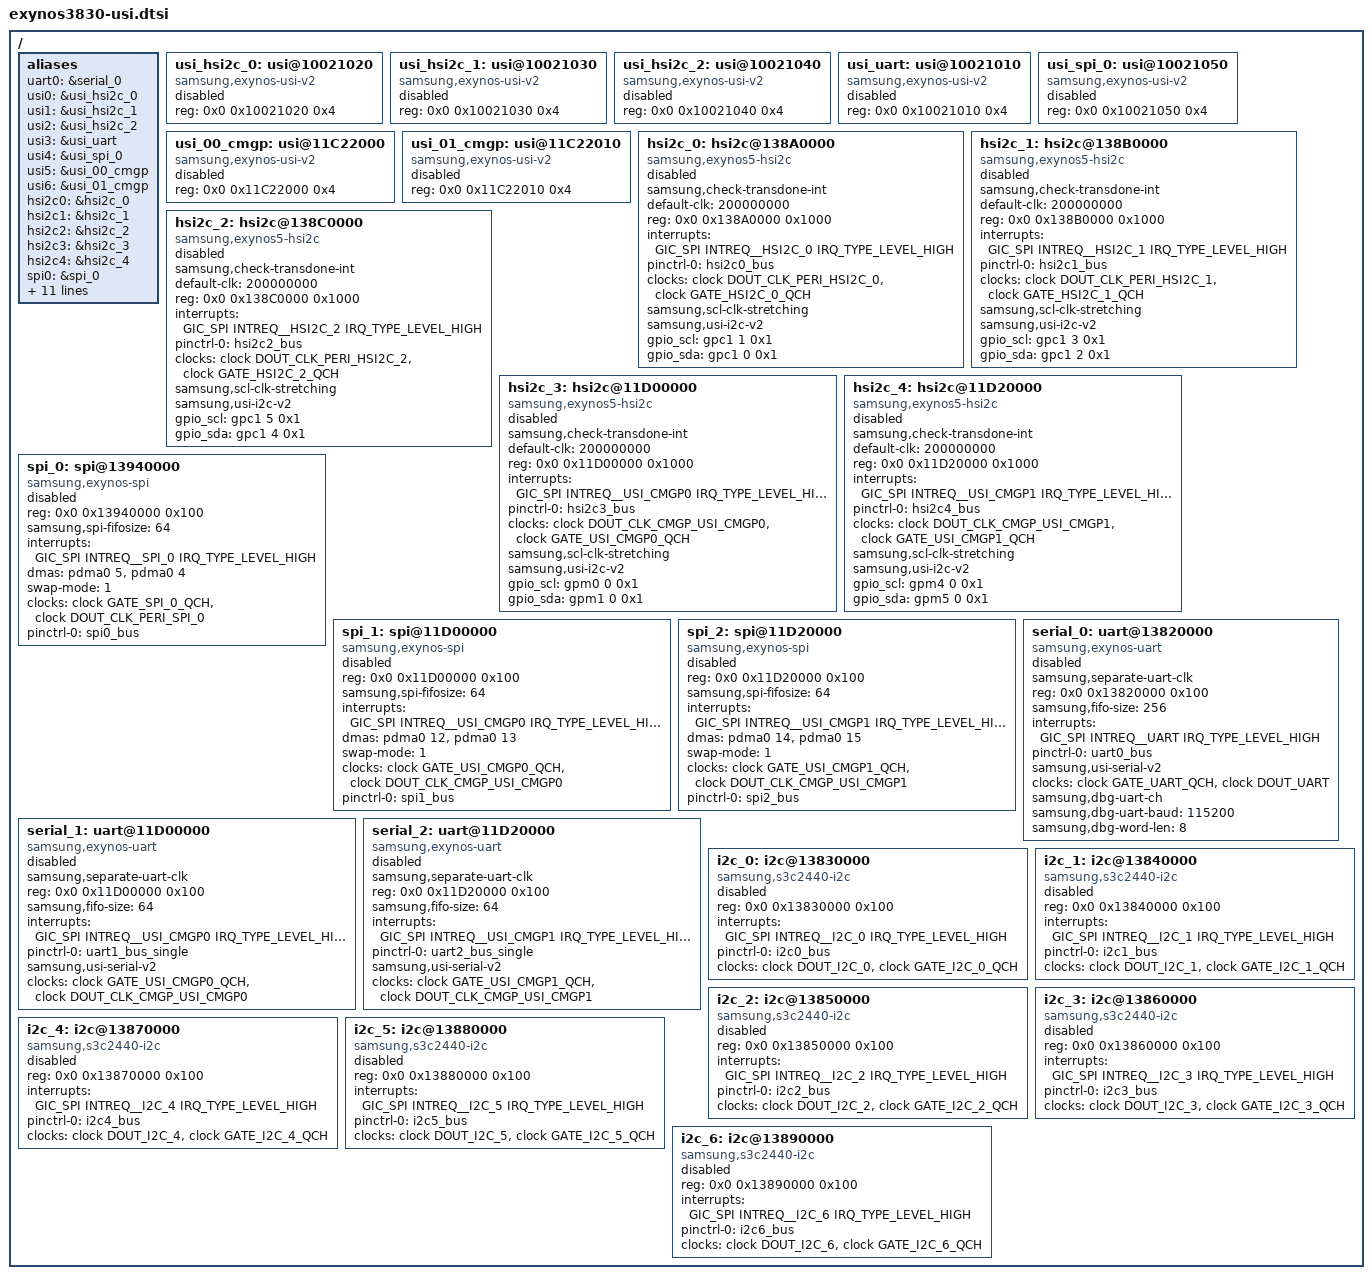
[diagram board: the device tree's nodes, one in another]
/*
 * Samsung's Exynos3830 SoC USI device tree source
 *
 * Copyright (c) 2019 Samsung Electronics Co., Ltd.
 *		http://www.samsung.com
 *
 * Samsung's Exynos3830 SoC USI channels are listed as device
 * tree nodes are listed in this file.
 *
 * This program is free software; you can redistribute it and/or modify
 * it under the terms of the GNU General Public License version 2 as
 * published by the Free Software Foundation.
*/

/ {
	aliases {
		uart0 = &serial_0;
		usi0 = &usi_hsi2c_0;
		usi1 = &usi_hsi2c_1;
		usi2 = &usi_hsi2c_2;
		usi3 = &usi_uart;
		usi4 = &usi_spi_0;
		usi5 = &usi_00_cmgp;
		usi6 = &usi_01_cmgp;
		hsi2c0 = &hsi2c_0;
		hsi2c1 = &hsi2c_1;
		hsi2c2 = &hsi2c_2;
		hsi2c3 = &hsi2c_3;
		hsi2c4 = &hsi2c_4;
		spi0 = &spi_0;
		spi1 = &spi_1;
		spi2 = &spi_2;
		uart1 = &serial_1;
		uart2 = &serial_2;
		i2c0 = &i2c_0;
		i2c1 = &i2c_1;
		i2c2 = &i2c_2;
		i2c3 = &i2c_3;
		i2c4 = &i2c_4;
		i2c5 = &i2c_5;
		i2c6 = &i2c_6;
	};

	/* USI_HSI2C_0 */
	usi_hsi2c_0: usi@10021020 {
		compatible = "samsung,exynos-usi-v2";
		reg = <0x0 0x10021020 0x4>;
		/*	usi_v2_mode = "i2c" or "spi" or "uart"	*/
		status = "disabled";
	};

	/* USI_HSI2C_1 */
	usi_hsi2c_1: usi@10021030 {
		compatible = "samsung,exynos-usi-v2";
		reg = <0x0 0x10021030 0x4>;
		/*	usi_v2_mode = "i2c" */
		status = "disabled";
	};

	/* USI_HSI2C_2 */
	usi_hsi2c_2: usi@10021040 {
		compatible = "samsung,exynos-usi-v2";
		reg = <0x0 0x10021040 0x4>;
		/*	usi_v2_mode = "i2c" or "spi" or "uart"	*/
		status = "disabled";
	};

	/* USI_UART */
	usi_uart: usi@10021010 {
		compatible = "samsung,exynos-usi-v2";
		reg = <0x0 0x10021010 0x4>;
		/*	usi_v2_mode = "i2c" */
		status = "disabled";
	};

	/* USI_SPI_0 */
	usi_spi_0: usi@10021050 {
		compatible = "samsung,exynos-usi-v2";
		reg = <0x0 0x10021050 0x4>;
		/*	usi_v2_mode = "i2c" or "spi" or "uart"	*/
		status = "disabled";
	};

	/* USI_CMGP_00 */
	usi_00_cmgp: usi@11C22000 {
		compatible = "samsung,exynos-usi-v2";
		reg = <0x0 0x11C22000 0x4>;
		/*	usi_v2_mode = "i2c" */
		status = "disabled";
	};

	/* USI_CMGP_01 */
	usi_01_cmgp: usi@11C22010 {
		compatible = "samsung,exynos-usi-v2";
		reg = <0x0 0x11C22010 0x4>;
		/*	usi_v2_mode = "i2c" or "spi" or "uart"	*/
		status = "disabled";
	};

	/* USI_HSI2C_0 */
	hsi2c_0: hsi2c@138A0000 {
		compatible = "samsung,exynos5-hsi2c";
		samsung,check-transdone-int;
		default-clk = <200000000>;
		reg = <0x0 0x138A0000 0x1000>;
		interrupts = <GIC_SPI INTREQ__HSI2C_0 IRQ_TYPE_LEVEL_HIGH>;
		#address-cells = <1>;
		#size-cells = <0>;
		pinctrl-names = "default";
		pinctrl-0 = <&hsi2c0_bus>;
		clocks = <&clock DOUT_CLK_PERI_HSI2C_0>, <&clock GATE_HSI2C_0_QCH>;
		clock-names = "ipclk_hsi2c", "gate_hsi2c_clk";
		samsung,scl-clk-stretching;
		samsung,usi-i2c-v2;
		gpio_scl= <&gpc1 1 0x1>;
		gpio_sda= <&gpc1 0 0x1>;
		status = "disabled";
	};

	/* USI_HSI2C_1 */
	hsi2c_1: hsi2c@138B0000 {
		compatible = "samsung,exynos5-hsi2c";
		samsung,check-transdone-int;
		default-clk = <200000000>;
		reg = <0x0 0x138B0000 0x1000>;
		interrupts = <GIC_SPI INTREQ__HSI2C_1 IRQ_TYPE_LEVEL_HIGH>;
		#address-cells = <1>;
		#size-cells = <0>;
		pinctrl-names = "default";
		pinctrl-0 = <&hsi2c1_bus>;
		clocks = <&clock DOUT_CLK_PERI_HSI2C_1>, <&clock GATE_HSI2C_1_QCH>;
		clock-names = "ipclk_hsi2c", "gate_hsi2c_clk";
		samsung,scl-clk-stretching;
		samsung,usi-i2c-v2;
		gpio_scl= <&gpc1 3 0x1>;
		gpio_sda= <&gpc1 2 0x1>;
		status = "disabled";
	};

	/* USI_HSI2C_2 */
	hsi2c_2: hsi2c@138C0000 {
		compatible = "samsung,exynos5-hsi2c";
		samsung,check-transdone-int;
		default-clk = <200000000>;
		reg = <0x0 0x138C0000 0x1000>;
		interrupts = <GIC_SPI INTREQ__HSI2C_2 IRQ_TYPE_LEVEL_HIGH>;
		#address-cells = <1>;
		#size-cells = <0>;
		pinctrl-names = "default";
		pinctrl-0 = <&hsi2c2_bus>;
		clocks = <&clock DOUT_CLK_PERI_HSI2C_2>, <&clock GATE_HSI2C_2_QCH>;
		clock-names = "ipclk_hsi2c", "gate_hsi2c_clk";
		samsung,scl-clk-stretching;
		samsung,usi-i2c-v2;
		gpio_scl= <&gpc1 5 0x1>;
		gpio_sda= <&gpc1 4 0x1>;
		status = "disabled";
	};

	/* USI_CMGP_00 */
	hsi2c_3: hsi2c@11D00000 {
		compatible = "samsung,exynos5-hsi2c";
		samsung,check-transdone-int;
		default-clk = <200000000>;
		reg = <0x0 0x11D00000 0x1000>;
		interrupts = <GIC_SPI INTREQ__USI_CMGP0 IRQ_TYPE_LEVEL_HIGH>;
		#address-cells = <1>;
		#size-cells = <0>;
		pinctrl-names = "default";
		pinctrl-0 = <&hsi2c3_bus>;
		clocks = <&clock DOUT_CLK_CMGP_USI_CMGP0>, <&clock GATE_USI_CMGP0_QCH>;
		clock-names = "ipclk_hsi2c", "gate_hsi2c_clk";
		samsung,scl-clk-stretching;
		samsung,usi-i2c-v2;
		gpio_scl= <&gpm0 0 0x1>;
		gpio_sda= <&gpm1 0 0x1>;
		status = "disabled";
	};

	/* USI_CMGP_01 */
	hsi2c_4: hsi2c@11D20000 {
		compatible = "samsung,exynos5-hsi2c";
		samsung,check-transdone-int;
		default-clk = <200000000>;
		reg = <0x0 0x11D20000 0x1000>;
		interrupts = <GIC_SPI INTREQ__USI_CMGP1 IRQ_TYPE_LEVEL_HIGH>;
		#address-cells = <1>;
		#size-cells = <0>;
		pinctrl-names = "default";
		pinctrl-0 = <&hsi2c4_bus>;
		clocks = <&clock DOUT_CLK_CMGP_USI_CMGP1>, <&clock GATE_USI_CMGP1_QCH>;
		clock-names = "ipclk_hsi2c", "gate_hsi2c_clk";
		samsung,scl-clk-stretching;
		samsung,usi-i2c-v2;
		gpio_scl= <&gpm4 0 0x1>;
		gpio_sda= <&gpm5 0 0x1>;
		status = "disabled";
	};

	/* USI_SPI_0 */
	spi_0: spi@13940000 {
		compatible = "samsung,exynos-spi";
		reg = <0x0 0x13940000 0x100>;
		samsung,spi-fifosize = <64>;
		interrupts = <GIC_SPI INTREQ__SPI_0 IRQ_TYPE_LEVEL_HIGH>;
/*
		dma-mode;
*/
		dmas = <&pdma0 5 &pdma0 4>;
		dma-names = "tx", "rx";
		swap-mode = <1>;
		#address-cells = <1>;
		#size-cells = <0>;
		clocks = <&clock GATE_SPI_0_QCH>, <&clock DOUT_CLK_PERI_SPI_0>;
		clock-names = "gate_spi_clk", "ipclk_spi";
		pinctrl-names = "default";
		pinctrl-0 = <&spi0_bus>;
		status = "disabled";
	};

	/* USI_CMGP_00 */
	spi_1: spi@11D00000 {
		compatible = "samsung,exynos-spi";
		reg = <0x0 0x11D00000 0x100>;
		samsung,spi-fifosize = <64>;
		interrupts = <GIC_SPI INTREQ__USI_CMGP0 IRQ_TYPE_LEVEL_HIGH>;
/*
		dma-mode;
*/
		dmas = <&pdma0 12 &pdma0 13>;
		dma-names = "tx", "rx";
		swap-mode = <1>;
		#address-cells = <1>;
		#size-cells = <0>;
		clocks = <&clock GATE_USI_CMGP0_QCH>, <&clock DOUT_CLK_CMGP_USI_CMGP0>;
		clock-names = "gate_spi_clk", "ipclk_spi";
		pinctrl-names = "default";
		pinctrl-0 = <&spi1_bus>;
		status = "disabled";
	};

	/* USI_CMGP_01 */
	spi_2: spi@11D20000 {
		compatible = "samsung,exynos-spi";
		reg = <0x0 0x11D20000 0x100>;
		samsung,spi-fifosize = <64>;
		interrupts = <GIC_SPI INTREQ__USI_CMGP1 IRQ_TYPE_LEVEL_HIGH>;
/*
		dma-mode;
*/
		dmas = <&pdma0 14 &pdma0 15>;
		dma-names = "tx", "rx";
		swap-mode = <1>;
		#address-cells = <1>;
		#size-cells = <0>;
		clocks = <&clock GATE_USI_CMGP1_QCH>, <&clock DOUT_CLK_CMGP_USI_CMGP1>;
		clock-names = "gate_spi_clk", "ipclk_spi";
		pinctrl-names = "default";
		pinctrl-0 = <&spi2_bus>;
		status = "disabled";
	};

	/* USI_UART */
	serial_0: uart@13820000 {
		compatible = "samsung,exynos-uart";
		samsung,separate-uart-clk;
		reg = <0x0 0x13820000 0x100>;
		samsung,fifo-size = <256>;
		interrupts = <GIC_SPI INTREQ__UART IRQ_TYPE_LEVEL_HIGH>;
/*
		dma-mode;
		dmas = <&pdma0 3 &pdma0 2>;
*/
		pinctrl-names = "default";
		pinctrl-0 = <&uart0_bus>;
		samsung,usi-serial-v2;
		clocks = <&clock GATE_UART_QCH>, <&clock DOUT_UART>;
		samsung,dbg-uart-ch;
		samsung,dbg-uart-baud = <115200>;
		samsung,dbg-word-len = <8>;
		clock-names = "gate_uart_clk0", "ipclk_uart0";
		status = "disabled";
	};

	/* USI_CMGP_00 */
	serial_1: uart@11D00000 {
		compatible = "samsung,exynos-uart";
		samsung,separate-uart-clk;
		reg = <0x0 0x11D00000 0x100>;
		samsung,fifo-size = <64>;
		interrupts = <GIC_SPI INTREQ__USI_CMGP0 IRQ_TYPE_LEVEL_HIGH>;
/*
		dma-mode;
		dmas = <&pdma0 12 &pdma0 13>;
*/
		pinctrl-names = "default";
		pinctrl-0 = <&uart1_bus_single>; /* or _bus_dual */
		samsung,usi-serial-v2;
		clocks = <&clock GATE_USI_CMGP0_QCH>, <&clock DOUT_CLK_CMGP_USI_CMGP0>;
		clock-names = "gate_uart_clk1", "ipclk_uart1";
		status = "disabled";
	};

	/* USI_CMGP_01 */
	serial_2: uart@11D20000 {
		compatible = "samsung,exynos-uart";
		samsung,separate-uart-clk;
		reg = <0x0 0x11D20000 0x100>;
		samsung,fifo-size = <64>;
		interrupts = <GIC_SPI INTREQ__USI_CMGP1 IRQ_TYPE_LEVEL_HIGH>;
/*
		dma-mode;
		dmas = <&pdma0 14 &pdma0 15>;
*/
		pinctrl-names = "default";
		pinctrl-0 = <&uart2_bus_single>; /* or _bus_dual */
		samsung,usi-serial-v2;
		clocks = <&clock GATE_USI_CMGP1_QCH>, <&clock DOUT_CLK_CMGP_USI_CMGP1>;
		clock-names = "gate_uart_clk2", "ipclk_uart2";
		status = "disabled";
	};

	/* I2C_0 */
	i2c_0: i2c@13830000 {
		compatible = "samsung,s3c2440-i2c";
		reg = <0x0 0x13830000 0x100>;
		interrupts = <GIC_SPI INTREQ__I2C_0 IRQ_TYPE_LEVEL_HIGH>;
		#address-cells = <1>;
		#size-cells = <0>;
		pinctrl-names = "default";
		pinctrl-0 = <&i2c0_bus>;
		clocks = <&clock DOUT_I2C_0>, <&clock GATE_I2C_0_QCH>;
		clock-names = "rate_i2c", "gate_i2c";
		status = "disabled";
	};

	/* I2C_1 */
	i2c_1: i2c@13840000 {
		compatible = "samsung,s3c2440-i2c";
		reg = <0x0 0x13840000 0x100>;
		interrupts = <GIC_SPI INTREQ__I2C_1 IRQ_TYPE_LEVEL_HIGH>;
		#address-cells = <1>;
		#size-cells = <0>;
		pinctrl-names = "default";
		pinctrl-0 = <&i2c1_bus>;
		clocks = <&clock DOUT_I2C_1>, <&clock GATE_I2C_1_QCH>;
		clock-names = "rate_i2c", "gate_i2c";
		status = "disabled";
	};

	/* I2C_2 */
	i2c_2: i2c@13850000 {
		compatible = "samsung,s3c2440-i2c";
		reg = <0x0 0x13850000 0x100>;
		interrupts = <GIC_SPI INTREQ__I2C_2 IRQ_TYPE_LEVEL_HIGH>;
		#address-cells = <1>;
		#size-cells = <0>;
		pinctrl-names = "default";
		pinctrl-0 = <&i2c2_bus>;
		clocks = <&clock DOUT_I2C_2>, <&clock GATE_I2C_2_QCH>;
		clock-names = "rate_i2c", "gate_i2c";
		status = "disabled";
	};

	/* I2C_3 */
	i2c_3: i2c@13860000 {
		compatible = "samsung,s3c2440-i2c";
		reg = <0x0 0x13860000 0x100>;
		interrupts = <GIC_SPI INTREQ__I2C_3 IRQ_TYPE_LEVEL_HIGH>;
		#address-cells = <1>;
		#size-cells = <0>;
		pinctrl-names = "default";
		pinctrl-0 = <&i2c3_bus>;
		clocks = <&clock DOUT_I2C_3>, <&clock GATE_I2C_3_QCH>;
		clock-names = "rate_i2c", "gate_i2c";
		status = "disabled";
	};

	/* I2C_4 */
	i2c_4: i2c@13870000 {
		compatible = "samsung,s3c2440-i2c";
		reg = <0x0 0x13870000 0x100>;
		interrupts = <GIC_SPI INTREQ__I2C_4 IRQ_TYPE_LEVEL_HIGH>;
		#address-cells = <1>;
		#size-cells = <0>;
		pinctrl-names = "default";
		pinctrl-0 = <&i2c4_bus>;
		clocks = <&clock DOUT_I2C_4>, <&clock GATE_I2C_4_QCH>;
		clock-names = "rate_i2c", "gate_i2c";
		status = "disabled";
	};

	/* I2C_5 | CAM_PMIC_I2C */
	i2c_5: i2c@13880000 {
		compatible = "samsung,s3c2440-i2c";
		reg = <0x0 0x13880000 0x100>;
		interrupts = <GIC_SPI INTREQ__I2C_5 IRQ_TYPE_LEVEL_HIGH>;
		#address-cells = <1>;
		#size-cells = <0>;
		pinctrl-names = "default";
		pinctrl-0 = <&i2c5_bus>;
		clocks = <&clock DOUT_I2C_5>, <&clock GATE_I2C_5_QCH>;
		clock-names = "rate_i2c", "gate_i2c";
		status = "disabled";
	};

	/* I2C_6 | MOTOR_I2C */
	i2c_6: i2c@13890000 {
		compatible = "samsung,s3c2440-i2c";
		reg = <0x0 0x13890000 0x100>;
		interrupts = <GIC_SPI INTREQ__I2C_6 IRQ_TYPE_LEVEL_HIGH>;
		#address-cells = <1>;
		#size-cells = <0>;
		pinctrl-names = "default";
		pinctrl-0 = <&i2c6_bus>;
		clocks = <&clock DOUT_I2C_6>, <&clock GATE_I2C_6_QCH>;
		clock-names = "rate_i2c", "gate_i2c";
		status = "disabled";
	};
};
